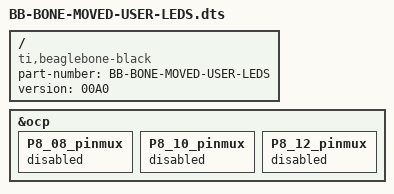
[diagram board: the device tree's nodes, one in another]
/* /opt/source/bb.org-overlays/src/arm/BB-BONE-MOVED-USER-LEDS.dts */

/dts-v1/;
/plugin/;

/ {
        compatible = "ti,beaglebone-black";

        /* identification */
        part-number = "BB-BONE-MOVED-USER-LEDS";
        version = "00A0";

        /*
         * Free up the pins to be used by the USER LED's from the pinmux helpers.
         */
        fragment@0 {
                target = <&ocp>;
                __overlay__ {
                        P8_08_pinmux { status = "disabled"; };   /* P8_8: Moved User LED's USER1 SD Card */
                        P8_10_pinmux { status = "disabled"; };   /* P8_10: Moved User LED's USER2 Kernel */
                        P8_12_pinmux { status = "disabled"; };   /* P8_12 Moved User LED's USER3 eMMC */
                };
        };

};









